AUTOSAR XML (schema 4-2-2)
package /AUTOSAR_BswM/SwComponentTypes
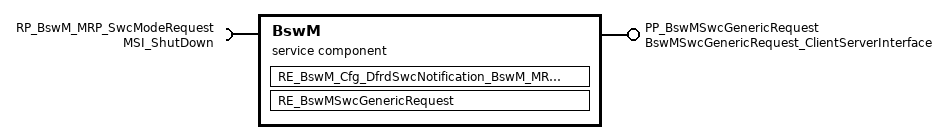
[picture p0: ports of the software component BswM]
  service sw component type BswM
    require port RP_BswM_MRP_SwcModeRequest: mode-switch-receiver-com-spec=supports-asynchronous-mode-switch=true, required-interface=MSI_ShutDown
    provide port PP_BswMSwcGenericRequest: provided-interface=BswMSwcGenericRequest_ClientServerInterface
    behavior IB_BswM: data-type-mapping=[ECUM_STATE_Mapping, MG_Shutdown_Mapping]
      swc mode switch event MSE_BswM_Cfg_DfrdSwcNotification_BswM_MRP_SwcModeRequest_SHUT_DOWN: start-on-event=RE_BswM_Cfg_DfrdSwcNotification_BswM_MRP_SwcModeRequest_SHUT_DOWN, activation=ON-ENTRY, mode=RP_BswM_MRP_SwcModeRequest.MDGP_MSI_ShutDown.SHUT_DOWN
      operation invoked event OPIE_BswMSwcGenericRequest_Server: start-on-event=RE_BswMSwcGenericRequest, operation=PP_BswMSwcGenericRequest.BswMSwcGenericRequest
      runnable RE_BswM_Cfg_DfrdSwcNotification_BswM_MRP_SwcModeRequest_SHUT_DOWN: can-be-invoked-concurrently=true, mode-access-point=RP_BswM_MRP_SwcModeRequest.MDGP_MSI_ShutDown, symbol=BswM_Cfg_DfrdSwcNotification_BswM_MRP_SwcModeRequest_SHUT_DOWN
      runnable RE_BswMSwcGenericRequest: can-be-invoked-concurrently=true, symbol=BswM_RequestMode
  client server interface BswMSwcGenericRequest_ClientServerInterface: is-service=true
    operation BswMSwcGenericRequest
      arg Requesting_user: type=BswM_UserType, direction=IN
      arg Requested_mode: type=BswM_ModeType, direction=IN
package /AUTOSAR_BswM/SwcImplementations
  swc implementation SWCIMPL_BswM: programming-language=C, sw-version=1.0.0, swc-bsw-mapping=BswM, behavior=IB_BswM
    code-descriptors:
      code CodeDescriptor: artifact-descriptors=autosar-engineering-object={short-label=ArEngObj, category=SWSRC}
package /AUTOSAR_BswM/SwcBswMappings
  swc bsw mapping BswM: bsw-behavior=IB_BswM, swc-behavior=IB_BswM
